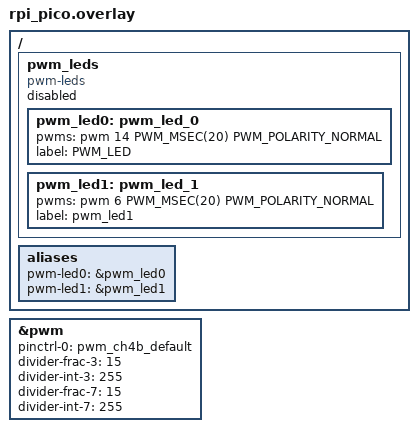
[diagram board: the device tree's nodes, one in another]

#include "rpi_pico-pinctrl.dtsi"

/ {
	pwm_leds {
		compatible = "pwm-leds";
		status = "disabled";
		pwm_led0: pwm_led_0 {
			pwms = <&pwm 14 PWM_MSEC(20) PWM_POLARITY_NORMAL>;
			label = "PWM_LED";
		};
		pwm_led1: pwm_led_1 {
			pwms = <&pwm 6 PWM_MSEC(20) PWM_POLARITY_NORMAL>;
			label = "pwm_led1";
		};

	};

	aliases {
		pwm-led0 = &pwm_led0;
		pwm-led1 = &pwm_led1;
	};
};

&pwm_led0 {
	status = "okay";
};
&pwm_led1 {
	status = "okay";
};



&pwm {
	pinctrl-0 = <&pwm_ch4b_default>;
	pinctrl-names = "default";

	status = "okay";

	divider-frac-3 = <15>;
	divider-int-3 = <255>;

	divider-frac-7 = <15>;
	divider-int-7 = <255>;
	
};

